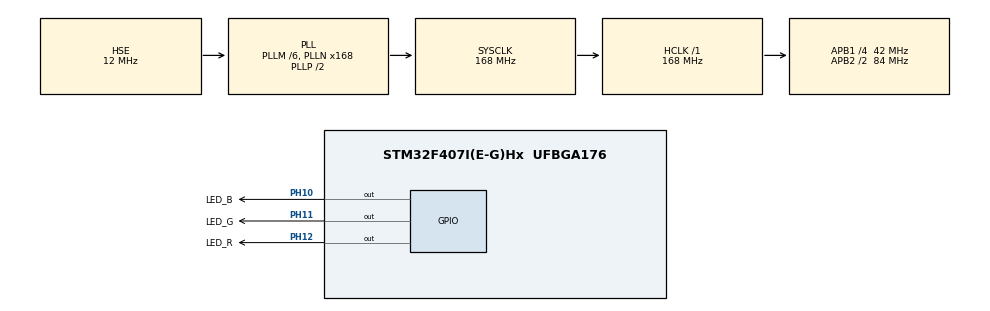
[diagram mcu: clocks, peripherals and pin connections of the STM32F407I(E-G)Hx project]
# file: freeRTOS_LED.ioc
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FREERTOS.Tasks01=LED_RED,0,128,red_led_task,As weak,NULL,Dynamic,NULL,NULL;LED_GREEN,2,128,green_led_task,As external,NULL,Dynamic,NULL,NULL
Mcu.Family=STM32F4
Mcu.Name=STM32F407I(E-G)Hx
Mcu.Package=UFBGA176
NVIC.PriorityGroup=NVIC_PRIORITYGROUP_4
PA13.Mode=Serial_Wire
PA13.Signal=SYS_JTMS-SWDIO
PA14.Mode=Serial_Wire
PA14.Signal=SYS_JTCK-SWCLK
PH0-OSC_IN.Mode=HSE-External-Oscillator
PH0-OSC_IN.Signal=RCC_OSC_IN
PH1-OSC_OUT.Mode=HSE-External-Oscillator
PH1-OSC_OUT.Signal=RCC_OSC_OUT
PH10.GPIO_Label=LED_B
PH10.GPIO_PuPd=GPIO_PULLUP
PH10.GPIO_Speed=GPIO_SPEED_FREQ_MEDIUM
PH10.PinState=GPIO_PIN_SET
PH10.Signal=GPIO_Output
PH11.GPIO_Label=LED_G
PH11.GPIO_PuPd=GPIO_PULLUP
PH11.GPIO_Speed=GPIO_SPEED_FREQ_MEDIUM
PH11.PinState=GPIO_PIN_SET
PH11.Signal=GPIO_Output
PH12.GPIO_Label=LED_R
PH12.GPIO_PuPd=GPIO_PULLUP
PH12.GPIO_Speed=GPIO_SPEED_FREQ_MEDIUM
PH12.PinState=GPIO_PIN_SET
PH12.Signal=GPIO_Output
ProjectManager.HeapSize=0x2000
ProjectManager.StackSize=0x2000
ProjectManager.TargetToolchain=MDK-ARM V5
RCC.48MHZClocksFreq_Value=48000000
RCC.AHBFreq_Value=168000000
RCC.APB1CLKDivider=RCC_HCLK_DIV4
RCC.APB1Freq_Value=42000000
RCC.APB1TimFreq_Value=84000000
RCC.APB2CLKDivider=RCC_HCLK_DIV2
RCC.APB2Freq_Value=84000000
RCC.APB2TimFreq_Value=168000000
RCC.CortexFreq_Value=168000000
RCC.HCLKFreq_Value=168000000
RCC.HSE_VALUE=12000000
RCC.HSI_VALUE=16000000
RCC.LSE_VALUE=32768
RCC.PLLM=6
RCC.PLLN=168
RCC.PLLQ=7
RCC.PLLSourceVirtual=RCC_PLLSOURCE_HSE
RCC.RCC_RTC_Clock_SourceVirtual=RCC_RTCCLKSOURCE_HSE_DIV30
RCC.RCC_RTC_Clock_Source_FROM_HSE=RCC_RTCCLKSOURCE_HSE_DIV30
RCC.SYSCLKFreq_VALUE=168000000
RCC.SYSCLKSource=RCC_SYSCLKSOURCE_PLLCLK
RCC.VCOOutputFreq_Value=336000000
VP_FREERTOS_VS_CMSIS_V1.Mode=CMSIS_V1
board=custom

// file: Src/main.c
/* USER CODE BEGIN Header */
/**
  ******************************************************************************
  * @file           : main.c
  * @brief          : Main program body
  ******************************************************************************
  * @attention
  *
  * <h2><center>&copy; Copyright (c) 2019 STMicroelectronics.
  * All rights reserved.</center></h2>
  *
  * This software component is licensed by ST under Ultimate Liberty license
  * SLA0044, the "License"; You may not use this file except in compliance with
  * the License. You may obtain a copy of the License at:
  *                             www.st.com/SLA0044
  *
  ******************************************************************************
  */
/* USER CODE END Header */

#include "main.h"
#include "cmsis_os.h"
#include "gpio.h"

/* USER CODE BEGIN Includes */

#include "red_led_task.h"
#include "green_led_task.h"
#include "blue_led_task.h"
/* USER CODE END Includes */

/* USER CODE BEGIN PV */
osThreadId blue_led_handle;

/* USER CODE END PV */

void SystemClock_Config(void);
void MX_FREERTOS_Init(void);

int main(void)
{

  /* MCU Configuration--------------------------------------------------------*/

  /* Reset of all peripherals, Initializes the Flash interface and the Systick. */
  HAL_Init();

  /* Configure the system clock */
  SystemClock_Config();

  /* Initialize all configured peripherals */
  MX_GPIO_Init();

  /* Call init function for freertos objects (in freertos.c) */
  MX_FREERTOS_Init();

  /* Start scheduler */
  osKernelStart();

  /* We should never get here as control is now taken by the scheduler */

  /* Infinite loop */
  while (1)
  {

  }
}

void SystemClock_Config(void)
{
  RCC_OscInitTypeDef RCC_OscInitStruct = {0};
  RCC_ClkInitTypeDef RCC_ClkInitStruct = {0};

  /** Configure the main internal regulator output voltage
  */
  __HAL_RCC_PWR_CLK_ENABLE();
  __HAL_PWR_VOLTAGESCALING_CONFIG(PWR_REGULATOR_VOLTAGE_SCALE1);
  /** Initializes the CPU, AHB and APB busses clocks
  */
  RCC_OscInitStruct.OscillatorType = RCC_OSCILLATORTYPE_HSE;
  RCC_OscInitStruct.HSEState = RCC_HSE_ON;
  RCC_OscInitStruct.PLL.PLLState = RCC_PLL_ON;
  RCC_OscInitStruct.PLL.PLLSource = RCC_PLLSOURCE_HSE;
  RCC_OscInitStruct.PLL.PLLM = 6;
  RCC_OscInitStruct.PLL.PLLN = 168;
  RCC_OscInitStruct.PLL.PLLP = RCC_PLLP_DIV2;
  RCC_OscInitStruct.PLL.PLLQ = 7;
  if (HAL_RCC_OscConfig(&RCC_OscInitStruct) != HAL_OK)
  {
    Error_Handler();
  }
  /** Initializes the CPU, AHB and APB busses clocks
  */
  RCC_ClkInitStruct.ClockType = RCC_CLOCKTYPE_HCLK|RCC_CLOCKTYPE_SYSCLK
                              |RCC_CLOCKTYPE_PCLK1|RCC_CLOCKTYPE_PCLK2;
  RCC_ClkInitStruct.SYSCLKSource = RCC_SYSCLKSOURCE_PLLCLK;
  RCC_ClkInitStruct.AHBCLKDivider = RCC_SYSCLK_DIV1;
  RCC_ClkInitStruct.APB1CLKDivider = RCC_HCLK_DIV4;
  RCC_ClkInitStruct.APB2CLKDivider = RCC_HCLK_DIV2;

  if (HAL_RCC_ClockConfig(&RCC_ClkInitStruct, FLASH_LATENCY_5) != HAL_OK)
  {
    Error_Handler();
  }
}

void Error_Handler(void)
{
}

/************************ (C) COPYRIGHT STMicroelectronics *****END OF FILE****/

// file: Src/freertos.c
/* USER CODE BEGIN Header */
/**
  ******************************************************************************
  * File Name          : freertos.c
  * Description        : Code for freertos applications
  ******************************************************************************
  * @attention
  *
  * <h2><center>&copy; Copyright (c) 2019 STMicroelectronics.
  * All rights reserved.</center></h2>
  *
  * This software component is licensed by ST under Ultimate Liberty license
  * SLA0044, the "License"; You may not use this file except in compliance with
  * the License. You may obtain a copy of the License at:
  *                             www.st.com/SLA0044
  *
  ******************************************************************************
  */
/* USER CODE END Header */

#include "FreeRTOS.h"
#include "task.h"
#include "main.h"
#include "cmsis_os.h"

/* USER CODE BEGIN PM */

extern void blue_led_task(void const * argument);
/* USER CODE END PM */

osThreadId LED_REDHandle;
osThreadId LED_GREENHandle;

/* USER CODE BEGIN FunctionPrototypes */

osThreadId led_blue_handle;
/* USER CODE END FunctionPrototypes */

void red_led_task(void const * argument);
extern void green_led_task(void const * argument);

void MX_FREERTOS_Init(void); /* (MISRA C 2004 rule 8.1) */

/* GetIdleTaskMemory prototype (linked to static allocation support) */
void vApplicationGetIdleTaskMemory( StaticTask_t **ppxIdleTaskTCBBuffer, StackType_t **ppxIdleTaskStackBuffer, uint32_t *pulIdleTaskStackSize );

/* USER CODE BEGIN GET_IDLE_TASK_MEMORY */
static StaticTask_t xIdleTaskTCBBuffer;
static StackType_t xIdleStack[configMINIMAL_STACK_SIZE];

void vApplicationGetIdleTaskMemory( StaticTask_t **ppxIdleTaskTCBBuffer, StackType_t **ppxIdleTaskStackBuffer, uint32_t *pulIdleTaskStackSize )
{
  *ppxIdleTaskTCBBuffer = &xIdleTaskTCBBuffer;
  *ppxIdleTaskStackBuffer = &xIdleStack[0];
  *pulIdleTaskStackSize = configMINIMAL_STACK_SIZE;
  /* place for user code */
}
/* USER CODE END GET_IDLE_TASK_MEMORY */

void MX_FREERTOS_Init(void) {

  /* Create the thread(s) */
  /* definition and creation of LED_RED */
  osThreadDef(LED_RED, red_led_task, osPriorityNormal, 0, 128);
  LED_REDHandle = osThreadCreate(osThread(LED_RED), NULL);

  /* definition and creation of LED_GREEN */
  osThreadDef(LED_GREEN, green_led_task, osPriorityHigh, 0, 128);
  LED_GREENHandle = osThreadCreate(osThread(LED_GREEN), NULL);

  /* USER CODE BEGIN RTOS_THREADS */
  /* add threads, ... */
  osThreadDef(LED_BLUE, blue_led_task, osPriorityHigh, 0, 128);
  led_blue_handle = osThreadCreate(osThread(LED_BLUE), NULL);
  /* USER CODE END RTOS_THREADS */

}

__weak void red_led_task(void const * argument)
{

  for(;;)
  {
    osDelay(1);
  }
}

/************************ (C) COPYRIGHT STMicroelectronics *****END OF FILE****/
